VERSION ""

NS_ :

BS_:

BU_: DBG MASTER GPS MOTOR SENSOR APP

BO_ 101 MOTOR_CMD: 1 MASTER
 SG_ MOTOR_CMD_steer : 0|4@1+ (1,-5) [-5|5] "" MOTOR
 SG_ MOTOR_CMD_drive : 4|4@1+ (1,0) [0|9] "" MOTOR

BO_ 400 MOTOR_STATUS: 3 MOTOR
 SG_ MOTOR_STATUS_wheel_error : 0|1@1+ (1,0) [0|0] "" MASTER,IO
 SG_ MOTOR_STATUS_speed_kph : 8|16@1+ (0.001,0) [0|0] "kph" MASTER,IO

BO_ 32 MASTER_HB: 2 MASTER
 SG_ MASTER_SPEED_cmd : 0|8@1+ (1,0) [0|0] "" SENSOR,MOTOR,GPS,APP
 SG_ MASTER_STEER_cmd : 8|8@1+ (1,0) [0|0] "" SENSOR,MOTOR,GPS,APP

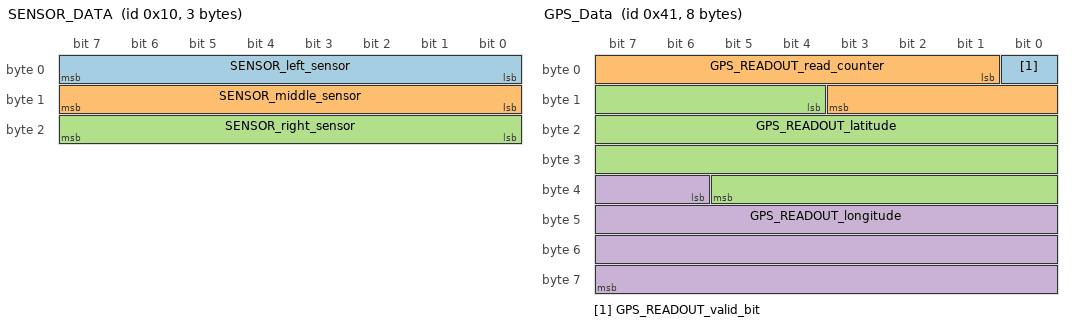
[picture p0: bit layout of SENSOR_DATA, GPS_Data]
BO_ 16 SENSOR_DATA: 3 SENSOR
 SG_ SENSOR_left_sensor : 0|8@1+ (1,0) [0|0] "" MASTER
 SG_ SENSOR_middle_sensor : 8|8@1+ (1,0) [0|0] "" MASTER
 SG_ SENSOR_right_sensor : 16|8@1+ (1,0) [0|0] "" MASTER

BO_ 48 MOTOR_HB: 1 MOTOR
 SG_ MOTOR_HEARTBEAT_cmd : 0|8@1+ (1,0) [0|0] "" MASTER

BO_ 65 GPS_Data: 8 GPS
 SG_ GPS_READOUT_valid_bit : 0|1@1+ (1,0) [0|1] "" MASTER,MOTOR
 SG_ GPS_READOUT_read_counter : 1|11@1+ (1,0) [0|2000] "" MASTER,MOTOR
 SG_ GPS_READOUT_latitude : 12|26@1+ (0.000001,0) [0|0] "" MASTER,MOTOR
 SG_ GPS_READOUT_longitude : 38|26@1- (0.000001,0) [0|0] "" MASTER,MOTOR

BO_ 80 APP_HB: 1 APP
 SG_ APP_HEARTBEAT_cmd : 0|8@1+ (1,0) [0|0] "" MASTER

BO_ 1 APP_START_STOP: 1 APP
 SG_ APP_START_STOP_cmd : 0|8@1+ (1,0) [0|0] "" MASTER

CM_ BU_ DRIVER "The driver controller driving the car";
CM_ BU_ MOTOR "The motor controller of the car";
CM_ BU_ SENSOR "The sensor controller of the car";
CM_ BU_ APP "The communication bridge controller of car";
CM_ BO_ 100 "Sync message used to synchronize the controllers";

BA_DEF_ "BusType" STRING ;
BA_DEF_ BO_ "GenMsgCycleTime" INT 0 0;
BA_DEF_ SG_ "FieldType" STRING ;

BA_DEF_DEF_ "BusType" "CAN";
BA_DEF_DEF_ "FieldType" "";
BA_DEF_DEF_ "GenMsgCycleTime" 0;

BA_ "GenMsgCycleTime" BO_ 500 100;
BA_ "GenMsgCycleTime" BO_ 100 1000;
BA_ "GenMsgCycleTime" BO_ 101 100;
BA_ "GenMsgCycleTime" BO_ 400 100;
BA_ "GenMsgCycleTime" BO_ 200 100;
BA_ "FieldType" SG_ 500 DBC_TEST1_enum "DBC_TEST1_enum";
BA_ "FieldType" SG_ 100 DRIVER_HEARTBEAT_cmd "DRIVER_HEARTBEAT_cmd";

VAL_ 500 DBC_TEST1_enum 2 "DBC_TEST1_enum_val_two" 1 "DBC_TEST1_enum_val_one" ;
VAL_ 100 DRIVER_HEARTBEAT_cmd 2 "DRIVER_HEARTBEAT_cmd_REBOOT" 1 "DRIVER_HEARTBEAT_cmd_SYNC" 0 "DRIVER_HEARTBEAT_cmd_NOOP" ;
